# ATSAMRH71F20B register map
Vendor: Microchip Technology; Series: SAMRH71; File version: 0
CPU: CM7 r1p1, little endian, MPU, FPU, 3 interrupt priority bits
Registers are 32-bit, read-write, reset 0x0 unless marked. A register's access mark holds for its fields unless they carry their own. Offsets are from the block's base; [hi:lo] are bit positions; {n}, {i} and the like mark numbered series; 'fields as' and 'values as' point back to an identical list.

## SPW
Base 0x40040000; register names take the prefix SPW_
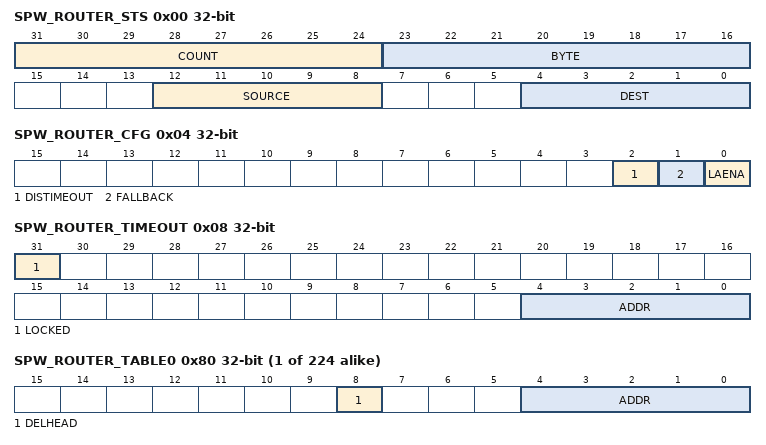
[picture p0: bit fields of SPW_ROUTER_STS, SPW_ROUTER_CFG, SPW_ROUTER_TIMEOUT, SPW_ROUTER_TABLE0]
0x00 SPW_ROUTER_STS ro — SpW Router Status
  [31:24] COUNT — Packet Count
  [23:16] BYTE — Router byte
  [12:8] SOURCE — Source address
  [4:0] DEST — Destination addr
0x04 SPW_ROUTER_CFG ro — SpW Router Config
  [2] DISTIMEOUT — Disable Timeout
  [1] FALLBACK — Fallback Routing
  [0] LAENA — LA Routing Enable
0x08 SPW_ROUTER_TIMEOUT ro
  [31] LOCKED
  [4:0] ADDR — Physical Address
{0x80+4i} SPW_ROUTER_TABLE{i} (i=0..223) — SpW Router Table (router_table_nb = 32) {i}
  [8] DELHEAD — Delete Header Byte
  [4:0] ADDR — Address
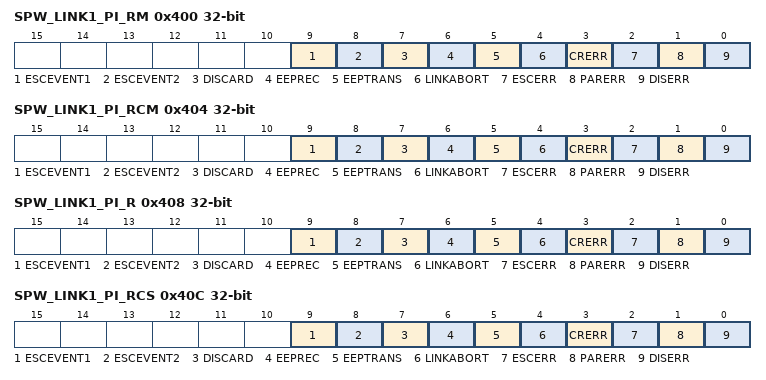
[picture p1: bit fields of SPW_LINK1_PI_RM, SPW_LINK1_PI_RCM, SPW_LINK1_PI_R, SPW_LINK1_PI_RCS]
0x400 SPW_LINK1_PI_RM ro — SpW Link 1 Pending Read Masked Interrupt
  [9] ESCEVENT1 — Escape Event 1
  [8] ESCEVENT2 — Escape Event 2
  [7] DISCARD
  [6] EEPREC — EEP received
  [5] EEPTRANS — EEP transmitted
  [4] LINKABORT
  [3] CRERR
  [2] ESCERR
  [1] PARERR
  [0] DISERR
0x404 SPW_LINK1_PI_RCM ro — SpW Link 1 Pending Read and Clear Masked Interrupt
  fields as SPW_LINK1_PI_RM
0x408 SPW_LINK1_PI_R ro — SpW Link 1 Pending Read Interrupt
  fields as SPW_LINK1_PI_RM
0x40C SPW_LINK1_PI_RCS — SpW Link 1 Pending Read, Clear and Enabed Interrupt
  fields as SPW_LINK1_PI_RM
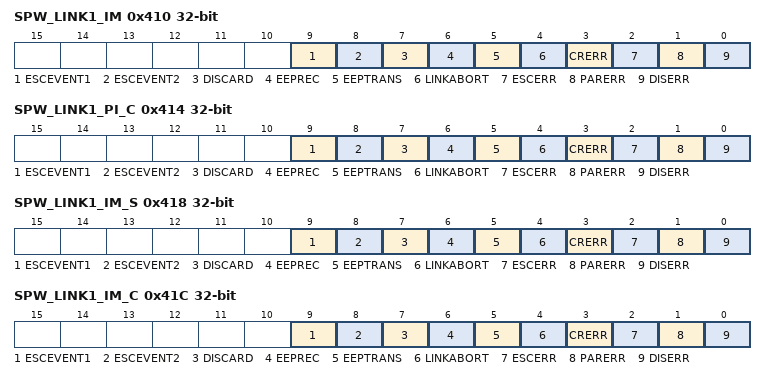
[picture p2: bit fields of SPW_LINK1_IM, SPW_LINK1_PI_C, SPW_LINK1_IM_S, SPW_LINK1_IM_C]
0x410 SPW_LINK1_IM — SpW Link 1 Interrupt Mask
  fields as SPW_LINK1_PI_RM
0x414 SPW_LINK1_PI_C wo — SpW Link 1 Clear Pending Interrupt
  fields as SPW_LINK1_PI_RM
0x418 SPW_LINK1_IM_S wo — SpW Link 1 Interrupt Set Mask
  fields as SPW_LINK1_PI_RM
0x41C SPW_LINK1_IM_C wo — SpW Link 1 Interrupt Clear Mask
  fields as SPW_LINK1_PI_RM
0x420 SPW_LINK1_CFG — SpW Link 1 Config
  [1:0] COMMAND
    0=LINK_DISABLE (The link proceeds directly to the ErrorReset state when reaching the Run state.); 1=NO_COMMAND (State is not actively changed.); 2=AUTO_START (The Codec will wait in state Ready until the first NULL character is received.); 3=LINK_START (SpaceWire link can proceed to Started state.)
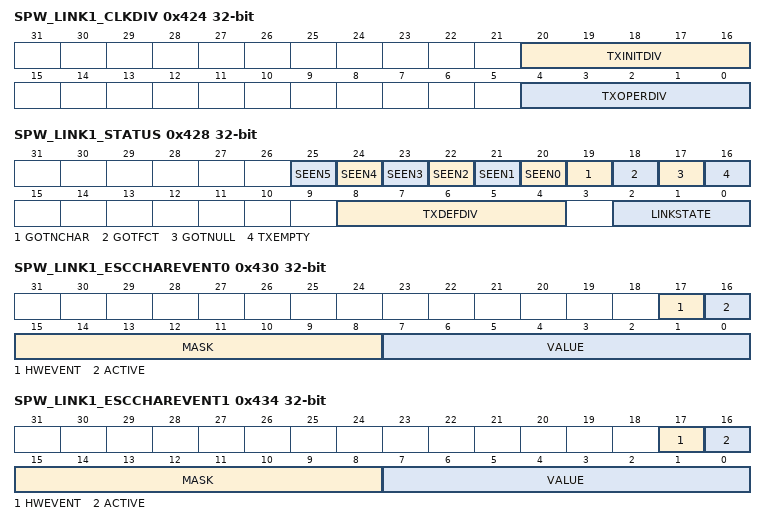
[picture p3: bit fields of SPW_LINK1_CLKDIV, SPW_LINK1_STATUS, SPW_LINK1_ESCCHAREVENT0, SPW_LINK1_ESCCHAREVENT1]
0x424 SPW_LINK1_CLKDIV — SpW Link 1 Clock Division
  [20:16] TXINITDIV, [4:0] TXOPERDIV
0x428 SPW_LINK1_STATUS ro
  [n+20] SEEN{n} (n=0..5)
  [19] GOTNCHAR
  [18] GOTFCT
  [17] GOTNULL
  [16] TXEMPTY
  [8:4] TXDEFDIV
  [2:0] LINKSTATE
    0=ERRORRESET (CODEC link state machine in ErrorReset state); 1=ERRORWAIT (CODEC link state machine in ErrorWait state); 2=READY (CODEC link state machine in Ready state); 3=STARTED (CODEC link state machine in Started state); 4=CONNECTING (CODEC link state machine in Connecting state); 5=RUN (CODEC link state machine in Run state)
0x42C SPW_LINK1_SWRESET — SpW Link 1 Software Reset
  [31:0] PATTERN
0x430 SPW_LINK1_ESCCHAREVENT0 — SpW Link 1 Escape Character Event 0
  [17] HWEVENT, [16] ACTIVE, [15:8] MASK, [7:0] VALUE
0x434 SPW_LINK1_ESCCHAREVENT1 — SpW Link 1 Escape Character Event 1
  [17] HWEVENT, [16] ACTIVE, [15:8] MASK, [7:0] VALUE
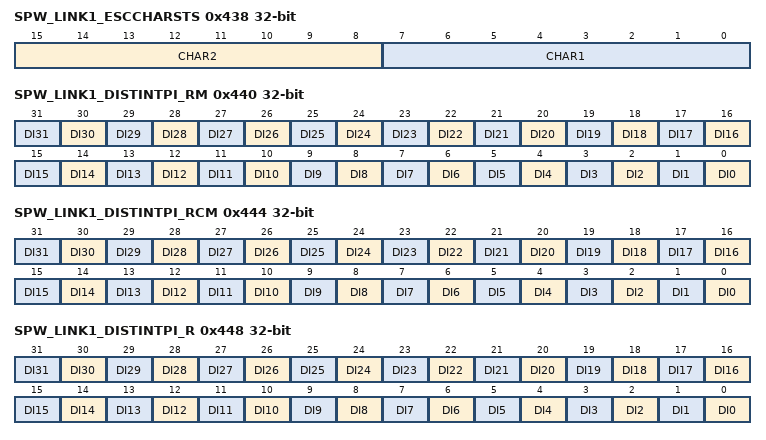
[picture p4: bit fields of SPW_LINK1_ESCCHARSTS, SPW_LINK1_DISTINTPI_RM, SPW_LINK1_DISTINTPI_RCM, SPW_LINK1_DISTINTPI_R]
0x438 SPW_LINK1_ESCCHARSTS ro — SpW Link 1 Escape Character Status
  [15:8] CHAR2 — Esc Char 2
  [7:0] CHAR1 — Esc Char 1
0x43C SPW_LINK1_TRANSESC — SpW Link 1 Transmit Escape Character
  [7:0] CHAR — Character
0x440 SPW_LINK1_DISTINTPI_RM ro — SpW Link 1 Distributed Interrupt Pending Read Masked Interrupt
  [n] DI{n} (n=0..31) — Distributed Interrupt
0x444 SPW_LINK1_DISTINTPI_RCM ro — SpW Link 1 Distributed Interrupt Pending Read and Clear Masked Interrupt
  [n] DI{n} (n=0..31) — Distributed Interrupt
0x448 SPW_LINK1_DISTINTPI_R ro — SpW Link 1 Distributed Interrupt Pending Read Interrupt
  [n] DI{n} (n=0..31) — Distributed Interrupt
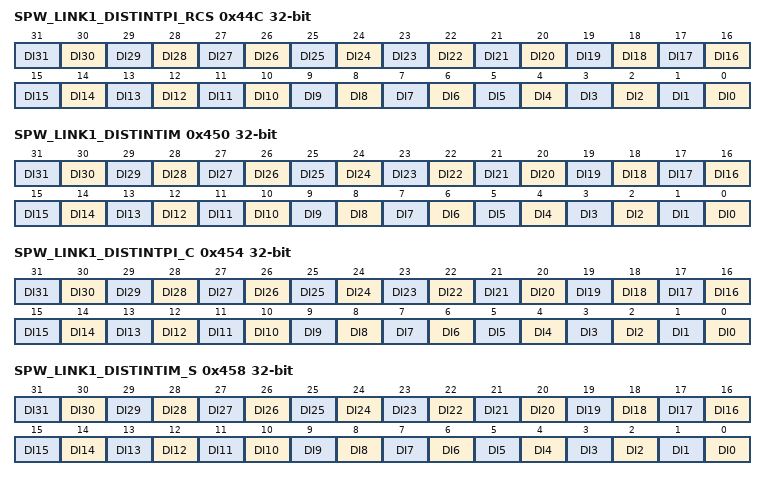
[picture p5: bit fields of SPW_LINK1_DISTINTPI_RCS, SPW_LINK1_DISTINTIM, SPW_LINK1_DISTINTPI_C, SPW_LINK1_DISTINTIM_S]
0x44C SPW_LINK1_DISTINTPI_RCS — SpW Link 1 Distributed Interrupt Pending Read and Clear Interrupt
  [n] DI{n} (n=0..31) — Distributed Interrupt
0x450 SPW_LINK1_DISTINTIM — SpW Link 1 Distributed Interrupt Mask
  [n] DI{n} (n=0..31) — Distributed Interrupt mask
0x454 SPW_LINK1_DISTINTPI_C wo — SpW Link 1 Distributed Interrupt Clear Pending Interrupt
  [n] DI{n} (n=0..31) — Distributed Interrupt
0x458 SPW_LINK1_DISTINTIM_S wo — SpW Link 1 Distributed Interrupt Set Mask
  [n] DI{n} (n=0..31) — Distributed Interrupt mask
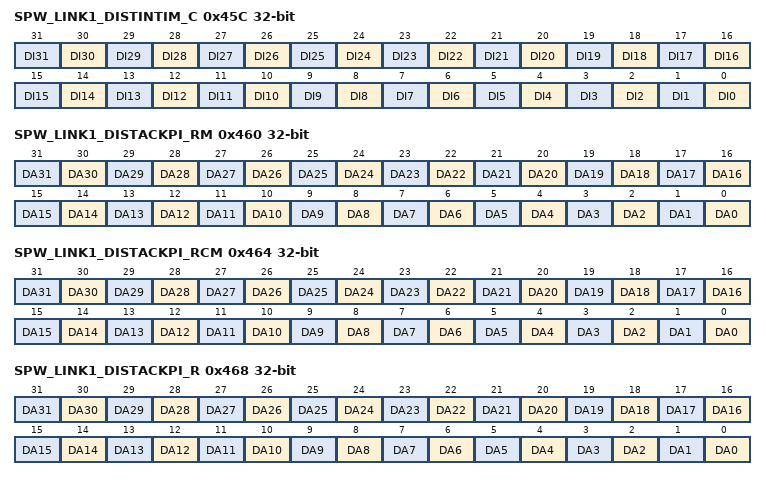
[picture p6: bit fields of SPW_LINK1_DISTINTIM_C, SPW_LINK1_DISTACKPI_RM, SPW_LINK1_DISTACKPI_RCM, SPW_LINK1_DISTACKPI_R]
0x45C SPW_LINK1_DISTINTIM_C wo — SpW Link 1 Distributed Interrupt Clear Mask
  [n] DI{n} (n=0..31) — Distributed Interrupt mask
0x460 SPW_LINK1_DISTACKPI_RM ro — SpW Link 1 Distributed Interrupt Acknowledge Pending Read Masked Interrupt
  [n] DA{n} (n=0..31) — Distributed Acknowledge
0x464 SPW_LINK1_DISTACKPI_RCM ro — SpW Link 1 Distributed Interrupt Acknowledge Pending Read and Clear Masked Interrupt
  [n] DA{n} (n=0..31) — Distributed Acknowledge
0x468 SPW_LINK1_DISTACKPI_R ro — SpW Link 1 Distributed Interrupt Acknowledge Pending Read Interrupt
  [n] DA{n} (n=0..31) — Distributed Acknowledge
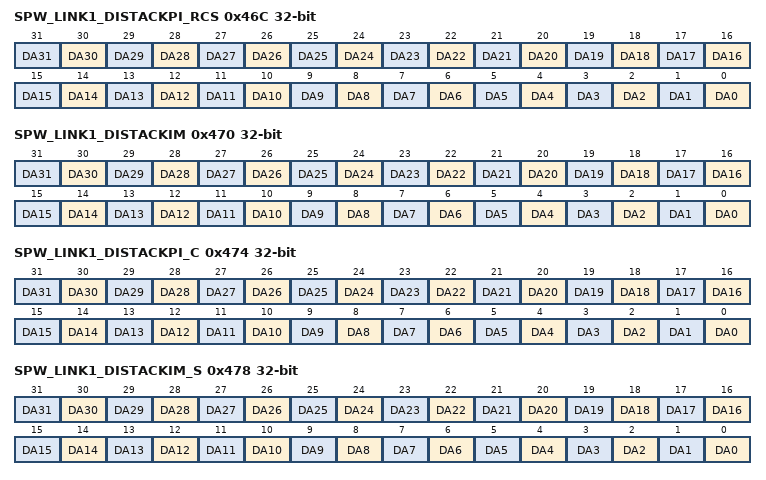
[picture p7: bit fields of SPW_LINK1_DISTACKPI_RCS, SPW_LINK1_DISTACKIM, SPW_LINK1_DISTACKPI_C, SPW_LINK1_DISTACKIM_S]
0x46C SPW_LINK1_DISTACKPI_RCS — SpW Link 1 Distributed Interrupt Acknowledge Pending Read and Clear Interrupt
  [n] DA{n} (n=0..31) — Distributed Acknowledge
0x470 SPW_LINK1_DISTACKIM — SpW Link 1 Distributed Interrupt Acknowledge Mask
  [n] DA{n} (n=0..31) — Distributed Acknowledge mask
0x474 SPW_LINK1_DISTACKPI_C wo — SpW Link 1 Distributed Interrupt Acknowledge Clear Pending Interrupt
  [n] DA{n} (n=0..31) — Distributed Acknowledge
0x478 SPW_LINK1_DISTACKIM_S wo — SpW Link 1 Distributed Interrupt Acknowledge Set Mask
  [n] DA{n} (n=0..31) — Distributed Acknowledge mask
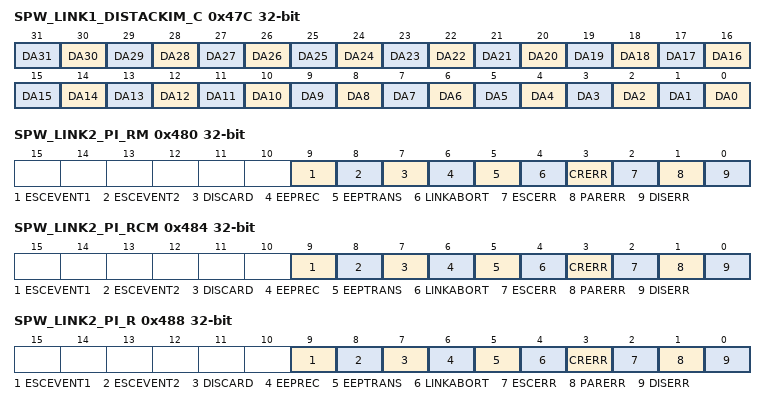
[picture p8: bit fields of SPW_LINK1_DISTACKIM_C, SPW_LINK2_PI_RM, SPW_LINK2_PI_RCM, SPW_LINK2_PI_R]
0x47C SPW_LINK1_DISTACKIM_C wo — SpW Link 1 Distributed Interrupt Acknowledge Clear Mask
  [n] DA{n} (n=0..31) — Distributed Acknowledge mask
0x480 SPW_LINK2_PI_RM ro — SpW Link 2 Pending Read Masked Interrupt
  fields as SPW_LINK1_PI_RM
0x484 SPW_LINK2_PI_RCM ro — SpW Link 2 Pending Read and Clear Masked Interrupt
  fields as SPW_LINK1_PI_RM
0x488 SPW_LINK2_PI_R ro — SpW Link 2 Pending Read Interrupt
  fields as SPW_LINK1_PI_RM
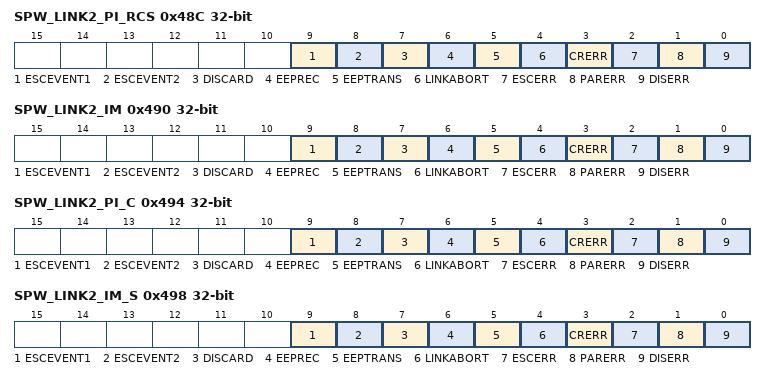
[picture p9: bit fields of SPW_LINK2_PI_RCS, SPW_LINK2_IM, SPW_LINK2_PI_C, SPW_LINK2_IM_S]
0x48C SPW_LINK2_PI_RCS — SpW Link 2 Pending Read, Clear and Enabled Interrupt
  fields as SPW_LINK1_PI_RM
0x490 SPW_LINK2_IM — SpW Link 2 Interrupt Mask
  fields as SPW_LINK1_PI_RM
0x494 SPW_LINK2_PI_C wo — SpW Link 2 Clear Pending Interrupt
  fields as SPW_LINK1_PI_RM
0x498 SPW_LINK2_IM_S wo — SpW Link 2 Interrupt Set Mask
  fields as SPW_LINK1_PI_RM
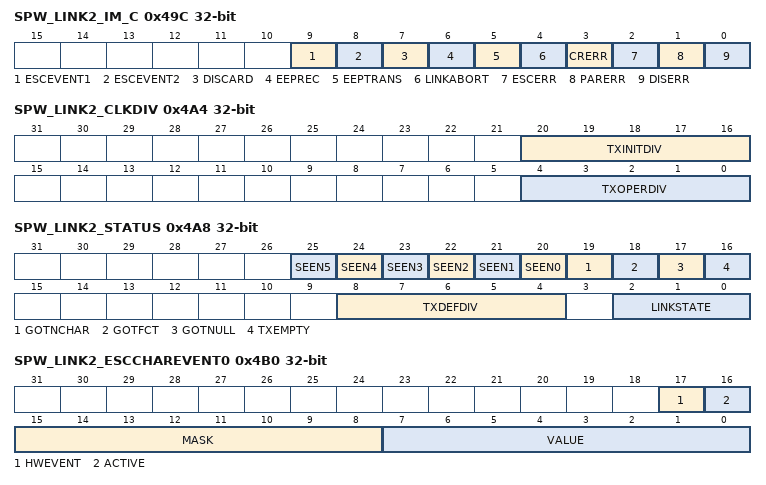
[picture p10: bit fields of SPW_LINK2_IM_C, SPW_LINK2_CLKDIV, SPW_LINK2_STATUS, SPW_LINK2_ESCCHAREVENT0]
0x49C SPW_LINK2_IM_C wo — SpW Link 2 Interrupt Clear Mask
  fields as SPW_LINK1_PI_RM
0x4A0 SPW_LINK2_CFG — SpW Link 2 Config
  fields as SPW_LINK1_CFG
0x4A4 SPW_LINK2_CLKDIV — SpW Link 2 Clock Division
  [20:16] TXINITDIV, [4:0] TXOPERDIV
0x4A8 SPW_LINK2_STATUS ro
  fields as SPW_LINK1_STATUS
0x4AC SPW_LINK2_SWRESET — SpW Link 2 Software Reset
  [31:0] PATTERN
0x4B0 SPW_LINK2_ESCCHAREVENT0 — SpW Link 2 Escape Character Event 0
  [17] HWEVENT, [16] ACTIVE, [15:8] MASK, [7:0] VALUE
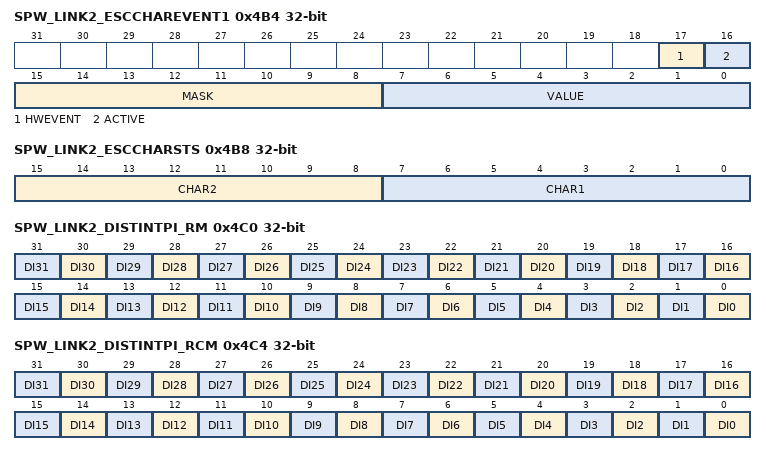
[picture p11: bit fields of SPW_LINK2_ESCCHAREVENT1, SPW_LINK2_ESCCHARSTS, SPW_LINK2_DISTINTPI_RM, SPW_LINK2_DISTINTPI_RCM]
0x4B4 SPW_LINK2_ESCCHAREVENT1 — SpW Link 2 Escape Character Event 1
  [17] HWEVENT, [16] ACTIVE, [15:8] MASK, [7:0] VALUE
0x4B8 SPW_LINK2_ESCCHARSTS ro — SpW Link 2 Escape Character Status
  [15:8] CHAR2 — Esc Char 2
  [7:0] CHAR1 — Esc Char 1
0x4BC SPW_LINK2_TRANSESC — SpW Link 2 Transmit Escape Character
  [7:0] CHAR — Character
0x4C0 SPW_LINK2_DISTINTPI_RM ro — SpW Link 2 Distributed Interrupt Pending Read Masked Interrupt
  [n] DI{n} (n=0..31) — Distributed Interrupt
0x4C4 SPW_LINK2_DISTINTPI_RCM ro — SpW Link 2 Distributed Interrupt Pending Read and Clear Masked Interrupt
  [n] DI{n} (n=0..31) — Distributed Interrupt
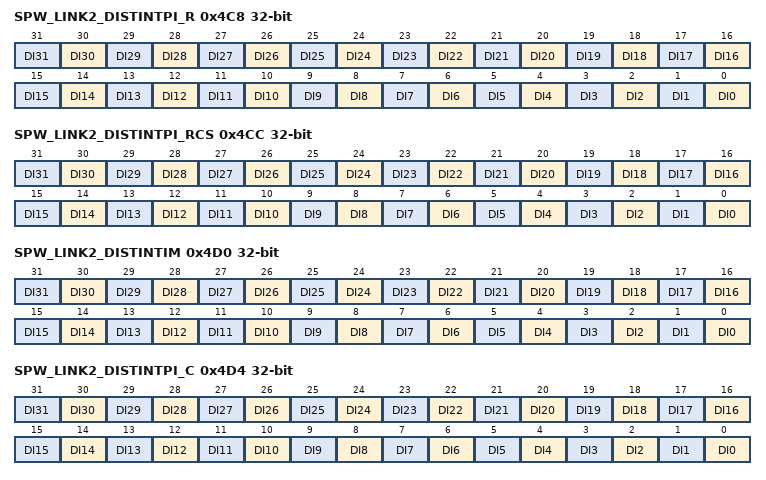
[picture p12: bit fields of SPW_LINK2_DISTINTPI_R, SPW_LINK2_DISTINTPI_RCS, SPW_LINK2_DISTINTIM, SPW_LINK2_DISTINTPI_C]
0x4C8 SPW_LINK2_DISTINTPI_R ro — SpW Link 2 Distributed Interrupt Pending Read Interrupt
  [n] DI{n} (n=0..31) — Distributed Interrupt
0x4CC SPW_LINK2_DISTINTPI_RCS — SpW Link 2 Distributed Interrupt Pending Read and Clear Interrupt
  [n] DI{n} (n=0..31) — Distributed Interrupt
0x4D0 SPW_LINK2_DISTINTIM — SpW Link 2 Distributed Interrupt Mask
  [n] DI{n} (n=0..31) — Distributed Interrupt mask
0x4D4 SPW_LINK2_DISTINTPI_C wo — SpW Link 2 Distributed Interrupt Clear Pending Interrupt
  [n] DI{n} (n=0..31) — Distributed Interrupt
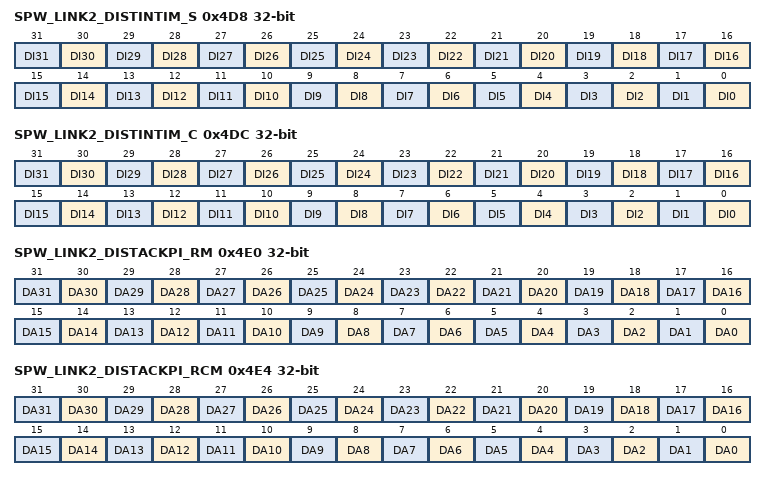
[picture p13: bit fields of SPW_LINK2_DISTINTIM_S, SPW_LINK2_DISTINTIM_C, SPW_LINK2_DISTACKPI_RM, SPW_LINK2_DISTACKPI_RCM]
0x4D8 SPW_LINK2_DISTINTIM_S wo — SpW Link 2 Distributed Interrupt Set Mask
  [n] DI{n} (n=0..31) — Distributed Interrupt mask
0x4DC SPW_LINK2_DISTINTIM_C wo — SpW Link 2 Distributed Interrupt Clear Mask
  [n] DI{n} (n=0..31) — Distributed Interrupt mask
0x4E0 SPW_LINK2_DISTACKPI_RM ro — SpW Link 2 Distributed Interrupt Acknowledge Pending Read Masked Interrupt
  [n] DA{n} (n=0..31) — Distributed Acknowledge
0x4E4 SPW_LINK2_DISTACKPI_RCM ro — SpW Link 2 Distributed Interrupt Acknowledge Pending Read and Clear Masked Interrupt
  [n] DA{n} (n=0..31) — Distributed Acknowledge
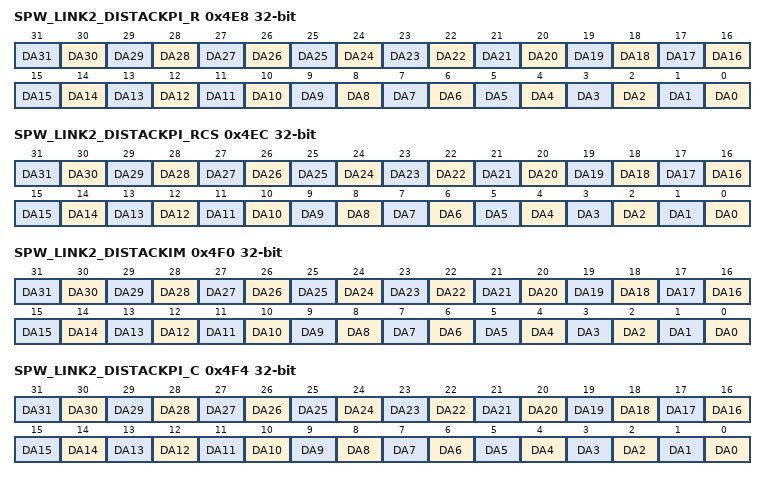
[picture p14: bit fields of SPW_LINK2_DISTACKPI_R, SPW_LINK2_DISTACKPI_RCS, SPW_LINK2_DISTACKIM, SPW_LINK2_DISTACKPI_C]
0x4E8 SPW_LINK2_DISTACKPI_R ro — SpW Link 2 Distributed Interrupt Acknowledge Pending Read Interrupt
  [n] DA{n} (n=0..31) — Distributed Acknowledge
0x4EC SPW_LINK2_DISTACKPI_RCS — SpW Link 2 Distributed Interrupt Acknowledge Pending Read and Clear Interrupt
  [n] DA{n} (n=0..31) — Distributed Acknowledge
0x4F0 SPW_LINK2_DISTACKIM — SpW Link 2 Distributed Interrupt Acknowledge Mask
  [n] DA{n} (n=0..31) — Distributed Acknowledge mask
0x4F4 SPW_LINK2_DISTACKPI_C wo — SpW Link 2 Distributed Interrupt Acknowledge Clear Pending Interrupt
  [n] DA{n} (n=0..31) — Distributed Acknowledge
0x4F8 SPW_LINK2_DISTACKIM_S wo — SpW Link 2 Distributed Interrupt Acknowledge Set Mask
  [n] DA{n} (n=0..31) — Distributed Acknowledge mask
0x4FC SPW_LINK2_DISTACKIM_C wo — SpW Link 2 Distributed Interrupt Acknowledge Clear Mask
  [n] DA{n} (n=0..31) — Distributed Acknowledge mask
0x800 SPW_PKTRX1_PI_RM ro — PktRx Pending Read Masked Interrupt
  [4] ACT — Activated
  [3] DISCARD — Packet Discard
  [2] EEP — EEP seen
  [1] EOP — EOP seen
  [0] DEACT — Deactivated
0x804 SPW_PKTRX1_PI_RCM ro — PktRx Pending Read and Clear Masked Interrupt
  fields as SPW_PKTRX1_PI_RM
0x808 SPW_PKTRX1_PI_R ro — PktRx Pending Read Interrupt
  fields as SPW_PKTRX1_PI_RM
0x80C SPW_PKTRX1_PI_RCS — PktRx Pending Read, Clear and Enabled Interrupt
  fields as SPW_PKTRX1_PI_RM
0x810 SPW_PKTRX1_IM — PktRx Interrupt Mask
  fields as SPW_PKTRX1_PI_RM
0x814 SPW_PKTRX1_PI_C wo — PktRx Clear Pending Interrupt
  fields as SPW_PKTRX1_PI_RM
0x818 SPW_PKTRX1_IM_S wo — PktRx Interrupt Set Mask
  fields as SPW_PKTRX1_PI_RM
0x81C SPW_PKTRX1_IM_C wo — PktRx Interrupt Clear Mask
  fields as SPW_PKTRX1_PI_RM
0x820 SPW_PKTRX1_CFG — PktRx Config
  [0] DISCARD
0x824 SPW_PKTRX1_STATUS ro — PktRx Status
  [21] DEACT — Deactivating
  [20] PENDING
  [19] ACT — Active
  [18] ARM — Armed
  [17] LOCKED
  [16] PACKET
  [15:0] COUNT — Packet Count
0x830 SPW_PKTRX1_NXTBUFDATAADDR — PktRx Next Buffer Data Address
  [31:0] ADDR — Address
0x834 SPW_PKTRX1_NXTBUFDATALEN — PktRx Next Buffer Data Length
  [23:0] LEN — Length
0x838 SPW_PKTRX1_NXTBUFPKTADDR — PktRx Next Buffer Packet Address
  [31:0] ADDR — Address
0x83C SPW_PKTRX1_NXTBUFCFG — PktRx Next Buffer Config
  [30] SPLIT — Split Pkt
  [23:22] START — Start Mode
    0=STARTVALUE (Start if any bit in Start Value matches an incom-ing event); 1=STARTNOW (Start immediately. Request a deactivation on next packet boundary.); 2=STARTTCH1 (Start if Start Value matches an incoming Time Code from Time Code Handler 1); 3=STARTTCH2 (Start if Start Value matches an incoming Time Code from Time Code Handler 2)
  [21:16] VALUE — Start Value
  [15:0] MAXCNT — Max Count
0x840 SPW_PKTRX1_CURBUFDATAADDR ro — PktRx Current Buffer Data Address
  [31:0] ADDR — Address
0x844 SPW_PKTRX1_CURBUFDATALEN ro — PktRx Current Buffer Data Length
  [23:0] LEN — Length
0x848 SPW_PKTRX1_CURBUFPKTADDR ro — PktRx Current Buffer Packet Address
  [31:0] ADDR — Address
0x84C SPW_PKTRX1_CURBUFCFG — PktRx Current Buffer Config
  [31] ABORT
  [30] SPLIT
  [15:0] MAXCNT — Max Count
0x850 SPW_PKTRX1_PREVBUFDATALEN ro — PktRx Previous Buffer Data Length
  [23:0] LEN — Length
0x854 SPW_PKTRX1_PREVBUFSTS ro — PktRx Previous Buffer Status
  [31] LOCKED
  [19] DMAERR — DMA Error
  [18] FULLD — Buffer Data Full
  [17] FULLI — Buffer Info Full
  [16] EEP — EEP seen
  [15:0] CNT — Count
0x87C SPW_PKTRX1_SWRESET — PktRx Software Reset
  [31:0] PATTERN
0xC00 SPW_PKTTX1_PI_RM ro — PktTx Pending Read Masked Interrupt
  [3] EEP — EEP sent
  [2] EOP — EOP sent
  [1] ACT — Activated
  [0] DEACT — Deactivated
0xC04 SPW_PKTTX1_PI_RCM ro — PktTx Pending Read and Clear Masked Interrupt
  fields as SPW_PKTTX1_PI_RM
0xC08 SPW_PKTTX1_PI_R ro — PktTx Pending Read Interrupt
  fields as SPW_PKTTX1_PI_RM
0xC0C SPW_PKTTX1_PI_RCS — PktTx Pending Read, Clear and Enabled Interrupt
  fields as SPW_PKTTX1_PI_RM
0xC10 SPW_PKTTX1_IM — PktTx Interrupt Mask
  fields as SPW_PKTTX1_PI_RM
0xC14 SPW_PKTTX1_PI_C wo — PktTx Clear Pending Interrupt
  fields as SPW_PKTTX1_PI_RM
0xC18 SPW_PKTTX1_IM_S wo — PktTx Interrupt Set Mask
  fields as SPW_PKTTX1_PI_RM
0xC1C SPW_PKTTX1_IM_C wo — PktTx Interrupt Clear Mask
  fields as SPW_PKTTX1_PI_RM
0xC20 SPW_PKTTX1_STATUS — PktTx Status
  [18:16] PREV — Previous
    0=NOINFO (No information. Field not locked.); 1=LASTSENDLISTOK (Last send list fully done); 2=ABORTEDMEMERR (Aborted due to memory access error.); 3=ABORTEDNEWSD (Aborted by new send list.); 4=ABORTEDUSERCMD (Aborted by direct user command.); 5=ABORTEDTIMEOUT (Aborted by timeout.)
  [3] DEACT — Deactivating
  [2] PENDING
  [1] ACT — Active
  [0] ARM — Armed
0xC24 SPW_PKTTX1_NXTSENDROUT — PktTx Next Send List Router Bytes
  [39-8n:32-8n] BYTE{n} (n=1..4)
0xC28 SPW_PKTTX1_NXTSENDADDR — PktTx Next Send List Address
  [31:0] ADDR — Address
0xC2C SPW_PKTTX1_NXTSENDCFG — PktTx Next Send List Config
  [29] ABORT
  [23:22] START — Start Mode
    0=STARTVALUE (Start if any bit in Start Value matches an incom-ing event); 1=STARTNOW (Start immediately, if possible); 2=STARTTCH1 (Start if Start Value matches an incoming Time Code from Time Code Handler 1); 3=STARTTCH2 (Start if Start Value matches an incoming Time Code from Time Code Handler 2)
  [16] VALUE — Start Value
  [15:0] LEN — Length
0xC30 SPW_PKTTX1_CURSENDROUT ro — PktTx Current Send List Router Bytes
  [39-8n:32-8n] BYTE{n} (n=1..4)
0xC34 SPW_PKTTX1_CURSENDADDR ro — PktTx Current Send List Address
  [31:0] ADDR — Address
0xC38 SPW_PKTTX1_CURSENDCFG — PktTx Current Send List Config
  [31] ABORT
  [15:0] LEN — Length
0xC3C SPW_PKTTX1_SWRESET — PktTx Software Reset
  [31:0] PATTERN
0xE00 SPW_RMAP1_CFG — SpW RMAP 1 Config
  [16] RMAPENA — RMAP Enable
  [15:8] TLA — Address
  [7:0] DESTKEY
0xE04 SPW_RMAP1_STS_RC ro — SpW RMAP 1 Read and Clear Status
  [8] VALID
  [7:0] ERRCODE — Error Code
    0=NOERROR (No error detected); 1=DMAERROR (Error while DMA accessing the internal bus, e.g. illegal address.); 2=RMAPERROR (Unused RMAP command according to [RMAP]); 3=DESTKEYERROR (Destination key error); 4=DATACRCERROR; 5=EOPERROR (Early EOP in header or data, i.e. EOP has been received with less data than expected from the RMAP command header.); 6=CARGOERROR (Cargo too large. Late EOP or EEP in data, i.e. EOP/EEP has been received with more data than expected from the RMAP command header.); 7=EEPERROR (Early EEP in data for RMAP commands. EEP has been received with less data or exactly as much as expected from the RMAP command header.); 10=CMDERROR (Authorisation error:Invalid or unsupported command.); 12=TLAERROR (Non-matching Target Logical Address.); 16=HEADERCRCERROR (Incorrect header CRC.); 17=PROTOCOLIDERROR (Protocol Identifier not supported.); 18=REPLYADDERROR (Unsupported reply address length)
0xE08 SPW_RMAP1_STS ro — SpW RMAP 1 Read Status
  fields as SPW_RMAP1_STS_RC
0xE80 SPW_TCH_PI_RM ro — SpW Tch Pending Read Masked Interrupt
  [4] EARLYWD — Early Watchdog
  [3] LATEWD — Late Watchdog
  [2] ANYTIMECODE
  [1] TIMECODE
  [0] TCEVENT
0xE84 SPW_TCH_PI_RCM ro — SpW Tch Pending Read and Clear Masked Interrupt
  fields as SPW_TCH_PI_RM
0xE88 SPW_TCH_PI_R ro — SpW Tch Pending Read Interrupt
  fields as SPW_TCH_PI_RM
0xE8C SPW_TCH_PI_RCS — SpW Tch Pending Read, Clear and Enabled Interrupt
  fields as SPW_TCH_PI_RM
0xE90 SPW_TCH_IM — SpW Tch Interrupt Mask
  fields as SPW_TCH_PI_RM
0xE94 SPW_TCH_PI_C wo — SpW Tch Clear Pending Interrupt
  fields as SPW_TCH_PI_RM
0xE98 SPW_TCH_IM_S wo — SpW Tch Interrupt Set Mask
  fields as SPW_TCH_PI_RM
0xE9C SPW_TCH_IM_C wo — SpW Tch Interrupt Clear Mask
  fields as SPW_TCH_PI_RM
0xEA0 SPW_TCH_CFGLISTEN — SpW Tch Config Listener
  [1] L2 — Listen link 2
  [0] L1 — Listen link 1
0xEA4 SPW_TCH_CFGSEND — SpW Tch Config Sender
  [1] S2 — Send link 2
  [0] S1 — Send link 1
0xEA8 SPW_TCH_CFG — SpW Tch Config
  [5:0] EVENT
0xEAC SPW_TCH_CFGRESTART — SpW Tch Config Restart
  [15] ONESHOT, [14] PPS, [8] EVENT, [5:0] VALUE
0xEB0 SPW_TCH_CFGTCEVENT — SpW Tch Config Tc Event
  [13:8] MASK, [5:0] VALUE
0xEB4 SPW_TCH_CFGWD — SpW Tch Config Watchdog
  [31:16] EARLY, [15:0] LATE
0xEB8 SPW_TCH_LASTTIMECODE
  [8] SEND — Send Now
  [5:0] VALUE
0xEBC SPW_TCH_SWRESET — SpW Tch Software Reset
  [31:0] PATTERN
0xF00 SPW_GROUP_IRQSTS1 ro — SpW Group Interrupt status 1
  [16] TCH — Time Code Handler
  [15] RX1
  [7] TX1
0xF04 SPW_GROUP_IRQSTS2 ro — SpW Group Interrupt status 2
  [23] Di1 — Distributed Interrupt 1
  [22] Dia1 — Distributed Interrupt Acknowledge, Link 1
  [21] Link1
  [20] Di2 — Distributed Interrupt 2
  [19] Dia2 — Distributed Interrupt Acknowledge, Link 2
  [18] Link2
0xF08 SPW_GROUP_EDACSTS ro — SpW Group Interrupt status
  [15:8] UNCORR — Uncorrectable Error
  [7:0] CORR — Correction Count
